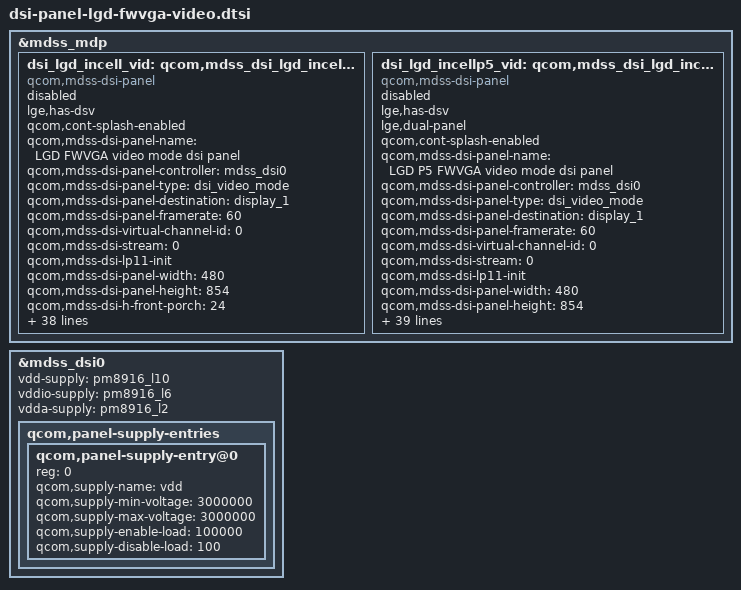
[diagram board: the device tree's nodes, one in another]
&mdss_mdp {
	dsi_lgd_incell_vid: qcom,mdss_dsi_lgd_incell_video{
		lge,has-dsv;
		compatible = "qcom,mdss-dsi-panel";
		status = "disable";
		qcom,cont-splash-enabled;
		qcom,mdss-dsi-panel-name = "LGD FWVGA video mode dsi panel";
		qcom,mdss-dsi-panel-controller = <&mdss_dsi0>;
		qcom,mdss-dsi-panel-type = "dsi_video_mode";
		qcom,mdss-dsi-panel-destination = "display_1";
		qcom,mdss-dsi-panel-framerate = <60>;
		qcom,mdss-dsi-virtual-channel-id = <0>;
		qcom,mdss-dsi-stream = <0>;
		qcom,mdss-dsi-lp11-init;
		qcom,mdss-dsi-panel-width = <480>;
		qcom,mdss-dsi-panel-height = <854>;
		qcom,mdss-dsi-h-front-porch = <24>;
		qcom,mdss-dsi-h-back-porch = <88>;
		qcom,mdss-dsi-h-pulse-width = <8>;
		qcom,mdss-dsi-h-sync-skew = <0>;
		qcom,mdss-dsi-v-back-porch = <12>;
		qcom,mdss-dsi-v-front-porch = <1070>;
		qcom,mdss-dsi-v-pulse-width = <4>;
		qcom,mdss-dsi-h-left-border = <0>;
		qcom,mdss-dsi-h-right-border = <0>;
		qcom,mdss-dsi-v-top-border = <0>;
		qcom,mdss-dsi-v-bottom-border = <0>;
		qcom,mdss-pan-physical-width-dimension = < 55 >;
		qcom,mdss-pan-physical-height-dimension = < 99 >;
		qcom,mdss-dsi-bpp = <24>;
		qcom,mdss-dsi-color-order = "rgb_swap_rgb";
		qcom,mdss-dsi-underflow-color = <0x0>;
		qcom,mdss-dsi-border-color = <0>;
		qcom,mdss-dsi-on-command = [
			/* 0. Manufacturer Command (Gamma on Time Control) */
			39 01 00 00 00 00 10
			F0 01 02 04 08 07 08 08 08 08 0C 1A 1B 1C 1E 44

			/* 1. GREF Control */
			39 01 00 00 00 00 08
			B7 00 1C 1C 1C 1C 1C 1C

			/* 2. DDV Control */
			39 01 00 00 00 00 07
			B6 06 0A 34 23 41 0A

			/* 3. VGH/VGL Control */
			39 01 00 00 00 00 05
			B8 00 42 12 F7

			/* 4. Manufacturer Commnad Access Project */
			15 01 00 00 00 00 02
			B0 00

			/* 5. GIP Control Set */
			39 01 00 00 00 00 0B
			B5 43 A0 01 12 06 00 00 00 00 48

			/* 6. Channel Control Set */
			39 01 00 00 00 00 07
			B4 01 09 02 02 02 02

			/* 7. Internal Timing Set */
			39 01 00 00 00 00 04
			B3 8B 7F 30

			/* 8. Panel Characteristics Set */
			39 01 00 00 00 00 03
			B2 00 03

			/* 9. RGB Interface Set */
			39 01 00 00 00 00 05
			B1 C6 1E 0F 00

			/* 10. VCL Control */
			39 01 00 00 00 00 04
			B9 00 03 04

			/* 11. VCOM Control2 */
			15 01 00 00 00 00 02
			BB 35

			/* 12. Set Address Mode */
			15 01 00 00 00 00 02
			36 00

			/* 13~15. Hidden Register */
			39 01 00 00 00 00 02
			D9 A0
			39 01 00 00 00 00 03
			F8 00 06
			39 01 00 00 00 00 03
			D7 00 B6

			/* 16. Bias Control */
			39 01 00 00 00 00 03
			BD 03 23

			/* 17. Set PWM Frequency */
			39 01 00 00 00 00 04
			C5 3F 00 50

			/* 18. PWM Output Polarity */
			15 01 00 00 00 00 02
			C4 00

			/* 19~24. Gamma Curve for RGB */
			39 01 00 00 00 00 0A
			D0 20 54 53 11 00 00 42 03 02
			39 01 00 00 00 00 0A
			D1 20 54 53 11 08 00 42 03 02
			39 01 00 00 00 00 0A
			D2 20 54 53 11 00 00 42 03 02
			39 01 00 00 00 00 0A
			D3 20 54 53 11 08 00 42 03 02
			39 01 00 00 00 00 0A
			D4 20 54 53 11 00 00 40 03 02
			39 01 00 00 00 00 0A
			D5 20 54 53 11 08 00 40 03 02

		];
		lge,display-on-cmds = [
			/* Set Gate Normal Operation */
			39 01 00 00 00 00 02
			FE 00

			/* Sleep Out */
			05 01 00 00 78 00 02
			11 00

			/* Display on */
			05 01 00 00 00 00 02
			29 00
		];
		qcom,mdss-dsi-off-command = [
			/* Sleep In */
			05 01 00 00 64 00 02
			10 00

			/* Set Gate Sig all GND */
			39 01 00 00 00 00 02
			FE 05

			/* Set MIPI Lane Floating */
			39 01 00 00 00 00 03
			D8 10 00
		];
		qcom,mdss-dsi-on-command-state = "dsi_lp_mode";
		qcom,mdss-dsi-off-command-state = "dsi_hs_mode";
		qcom,mdss-dsi-h-sync-pulse = <0>;
		qcom,mdss-dsi-traffic-mode = "non_burst_sync_event";
		qcom,mdss-dsi-lane-map = "lane_map_0123";
		//qcom,mdss-dsi-hfp-power-mode;
		//qcom,mdss-dsi-hbp-power-mode;
		//qcom,mdss-dsi-hsa-power-mode;
		qcom,mdss-dsi-bllp-eof-power-mode;
		//qcom,mdss-dsi-bllp-power-mode;
		qcom,mdss-dsi-lane-0-state;
		qcom,mdss-dsi-lane-1-state;
		qcom,mdss-dsi-panel-timings = [DB 34 22 00 64 66 28 38 2B 03 04 00];
		qcom,mdss-dsi-t-clk-post = <0x03>;
		qcom,mdss-dsi-t-clk-pre = <0x29>;
		//qcom,mdss-dsi-bl-min-level = <1>;
		//qcom,mdss-dsi-bl-max-level = <4095>;
		qcom,mdss-dsi-dma-trigger = "trigger_sw";
		qcom,mdss-dsi-mdp-trigger = "none";
		//qcom,mdss-dsi-bl-pmic-control-type = "bl_ctrl_wled";
		qcom,mdss-dsi-reset-sequence = <1 20>, <0 20>, <1 20>;
	};
	dsi_lgd_incellp5_vid: qcom,mdss_dsi_lgd_incellp5_fwvga_video{
		lge,has-dsv;
		compatible = "qcom,mdss-dsi-panel";
		status = "disable";
		lge,dual-panel;
		qcom,cont-splash-enabled;
		qcom,mdss-dsi-panel-name = "LGD P5 FWVGA video mode dsi panel";
		qcom,mdss-dsi-panel-controller = <&mdss_dsi0>;
		qcom,mdss-dsi-panel-type = "dsi_video_mode";
		qcom,mdss-dsi-panel-destination = "display_1";
		qcom,mdss-dsi-panel-framerate = <60>;
		qcom,mdss-dsi-virtual-channel-id = <0>;
		qcom,mdss-dsi-stream = <0>;
		qcom,mdss-dsi-lp11-init;
		qcom,mdss-dsi-panel-width = <480>;
		qcom,mdss-dsi-panel-height = <854>;
		qcom,mdss-dsi-h-front-porch = <24>;
		qcom,mdss-dsi-h-back-porch = <88>;
		qcom,mdss-dsi-h-pulse-width = <8>;
		qcom,mdss-dsi-h-sync-skew = <0>;
		qcom,mdss-dsi-v-back-porch = <12>;
		qcom,mdss-dsi-v-front-porch = <1070>;
		qcom,mdss-dsi-v-pulse-width = <4>;
		qcom,mdss-dsi-h-left-border = <0>;
		qcom,mdss-dsi-h-right-border = <0>;
		qcom,mdss-dsi-v-top-border = <0>;
		qcom,mdss-dsi-v-bottom-border = <0>;
		qcom,mdss-pan-physical-width-dimension = < 55 >;
		qcom,mdss-pan-physical-height-dimension = < 99 >;
		qcom,mdss-dsi-bpp = <24>;
		qcom,mdss-dsi-color-order = "rgb_swap_rgb";
		qcom,mdss-dsi-underflow-color = <0x0>;
		qcom,mdss-dsi-border-color = <0>;
		qcom,mdss-dsi-on-command = [
			/* 0. Manufacturer Command (Gamma on Time Control) */
			39 01 00 00 00 00 10
			F0 01 02 04 08 07 08 08 08 08 0C 1A 1B 1C 1E 44

			/* 1. GREF Control */
			39 01 00 00 00 00 08
			B7 00 1C 1C 1C 1C 1C 1C

			/* 2. DDV Control */
			39 01 00 00 00 00 07
			B6 06 0A 34 23 41 0A

			/* 3. VGH/VGL Control */
			39 01 00 00 00 00 05
			B8 00 42 12 F7

			/* 4. Manufacturer Commnad Access Protect */
			15 01 00 00 00 00 02
			B0 00

			/* 5. GIP Control Set */
			39 01 00 00 00 00 0B
			B5 43 A0 01 12 06 00 00 00 00 48

			/* 6. Channel Control Set */
			39 01 00 00 00 00 07
			B4 01 09 02 02 02 02

			/* 7. Internal Timing Set */
			39 01 00 00 00 00 04
			B3 8B 7F 30

			/* 8. Panel Characteristics Set */
			39 01 00 00 00 00 03
			B2 00 03

			/* 9. RGB Interface Set */
			39 01 00 00 00 00 05
			B1 C6 1E 0F 00

			/* 10. VCL Control */
			39 01 00 00 00 00 04
			B9 00 03 04

			/* 11. VCOM Control2 */
			15 01 00 00 00 00 02
			BB 2A

			/* 12. Set Address Mode */
			15 01 00 00 00 00 02
			36 00

			/* 13~15. Hidden Register */
			39 01 00 00 00 00 02
			D9 A0
			39 01 00 00 00 00 03
			F8 00 06
			39 01 00 00 00 00 03
			D7 00 B6

			/* 16. Bias Control */
			39 01 00 00 00 00 03
			BD 03 23

			/* 17. Set PWM Frequency */
			39 01 00 00 00 00 04
			C5 3F 00 50

			/* 18. PWM Output Polarity */
			15 01 00 00 00 00 02
			C4 00

			/* 19~24. Gamma Curve for RGB */
			39 01 00 00 00 00 0A
			D0 20 54 55 13 00 00 42 03 02
			39 01 00 00 00 00 0A
			D1 20 54 55 13 00 00 42 03 02
			39 01 00 00 00 00 0A
			D2 20 54 55 13 00 00 42 03 02
			39 01 00 00 00 00 0A
			D3 20 54 55 13 00 00 42 03 02
			39 01 00 00 00 00 0A
			D4 20 54 55 13 00 00 42 03 02
			39 01 00 00 00 00 0A
			D5 20 54 55 13 00 00 42 03 02

		];
		lge,display-on-cmds = [
			/* Set Gate Normal Operation */
			39 01 00 00 00 00 02
			FE 00

			/* Sleep Out */
			05 01 00 00 78 00 02
			11 00

			/* Display on */
			05 01 00 00 00 00 02
			29 00
		];
		qcom,mdss-dsi-off-command = [
			/* Sleep In */
			05 01 00 00 64 00 02
			10 00

			/* Set Gate Sig all GND */
			39 01 00 00 00 00 02
			FE 05

			/* Set MIPI Lane Floating */
			39 01 00 00 00 00 03
			D8 10 00
		];
		qcom,mdss-dsi-on-command-state = "dsi_lp_mode";
		qcom,mdss-dsi-off-command-state = "dsi_hs_mode";
		qcom,mdss-dsi-h-sync-pulse = <0>;
		qcom,mdss-dsi-traffic-mode = "non_burst_sync_event";
		qcom,mdss-dsi-lane-map = "lane_map_0123";
		//qcom,mdss-dsi-hfp-power-mode;
		//qcom,mdss-dsi-hbp-power-mode;
		//qcom,mdss-dsi-hsa-power-mode;
		qcom,mdss-dsi-bllp-eof-power-mode;
		//qcom,mdss-dsi-bllp-power-mode;
		qcom,mdss-dsi-lane-0-state;
		qcom,mdss-dsi-lane-1-state;
		qcom,mdss-dsi-panel-timings = [DB 34 22 00 64 66 28 38 2B 03 04 00];
		qcom,mdss-dsi-t-clk-post = <0x03>;
		qcom,mdss-dsi-t-clk-pre = <0x29>;
		//qcom,mdss-dsi-bl-min-level = <1>;
		//qcom,mdss-dsi-bl-max-level = <4095>;
		qcom,mdss-dsi-dma-trigger = "trigger_sw";
		qcom,mdss-dsi-mdp-trigger = "none";
		//qcom,mdss-dsi-bl-pmic-control-type = "bl_ctrl_wled";
		qcom,mdss-dsi-reset-sequence = <1 20>, <0 20>, <1 20>;
	};
};

&mdss_dsi0 {
	vdd-supply = <&pm8916_l10>;
	vddio-supply = <&pm8916_l6>;
	vdda-supply = <&pm8916_l2>;
	qcom,panel-supply-entries {
		qcom,panel-supply-entry@0 {
			reg = <0>;
			qcom,supply-name = "vdd";
			qcom,supply-min-voltage = <3000000>;
			qcom,supply-max-voltage = <3000000>;
			qcom,supply-enable-load = <100000>;
			qcom,supply-disable-load = <100>;

		};
	};
};
